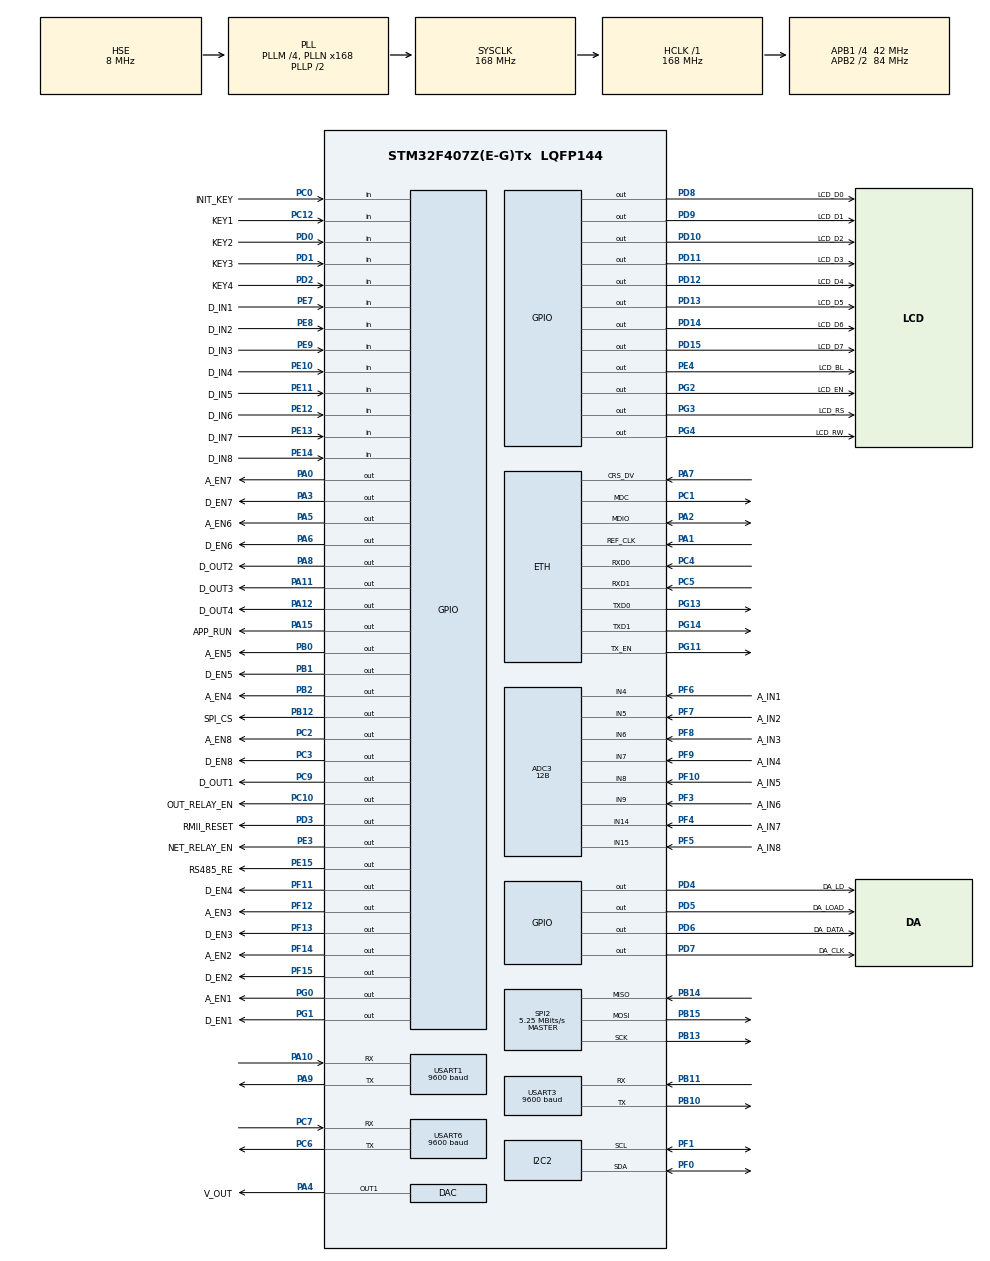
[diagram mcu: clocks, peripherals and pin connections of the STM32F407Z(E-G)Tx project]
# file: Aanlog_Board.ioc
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ADC3.Channel-0\#ChannelRegularConversion=ADC_CHANNEL_4
ADC3.Channel-1\#ChannelRegularConversion=ADC_CHANNEL_5
ADC3.Channel-2\#ChannelRegularConversion=ADC_CHANNEL_6
ADC3.Channel-3\#ChannelRegularConversion=ADC_CHANNEL_7
ADC3.Channel-4\#ChannelRegularConversion=ADC_CHANNEL_8
ADC3.Channel-5\#ChannelRegularConversion=ADC_CHANNEL_9
ADC3.Channel-6\#ChannelRegularConversion=ADC_CHANNEL_14
ADC3.Channel-7\#ChannelRegularConversion=ADC_CHANNEL_15
ADC3.ClockPrescaler=ADC_CLOCK_SYNC_PCLK_DIV4
ADC3.ContinuousConvMode=ENABLE
ADC3.DMAContinuousRequests=ENABLE
ADC3.DataAlign=ADC_DATAALIGN_RIGHT
ADC3.DiscontinuousConvMode=DISABLE
ADC3.EOCSelection=ADC_EOC_SINGLE_CONV
ADC3.EnableAnalogWatchDog=false
ADC3.ExternalTrigConv=ADC_SOFTWARE_START
ADC3.ExternalTrigConvEdge=ADC_EXTERNALTRIGCONVEDGE_NONE
ADC3.InjNumberOfConversion=0
ADC3.NbrOfConversion=8
ADC3.NbrOfConversionFlag=1
ADC3.Rank-0\#ChannelRegularConversion=1
ADC3.Rank-1\#ChannelRegularConversion=2
ADC3.Rank-2\#ChannelRegularConversion=3
ADC3.Rank-3\#ChannelRegularConversion=4
ADC3.Rank-4\#ChannelRegularConversion=5
ADC3.Rank-5\#ChannelRegularConversion=6
ADC3.Rank-6\#ChannelRegularConversion=7
ADC3.Rank-7\#ChannelRegularConversion=8
ADC3.Resolution=ADC_RESOLUTION_12B
ADC3.SamplingTime-0\#ChannelRegularConversion=ADC_SAMPLETIME_3CYCLES
ADC3.SamplingTime-1\#ChannelRegularConversion=ADC_SAMPLETIME_3CYCLES
ADC3.SamplingTime-2\#ChannelRegularConversion=ADC_SAMPLETIME_3CYCLES
ADC3.SamplingTime-3\#ChannelRegularConversion=ADC_SAMPLETIME_3CYCLES
ADC3.SamplingTime-4\#ChannelRegularConversion=ADC_SAMPLETIME_3CYCLES
ADC3.SamplingTime-5\#ChannelRegularConversion=ADC_SAMPLETIME_3CYCLES
ADC3.SamplingTime-6\#ChannelRegularConversion=ADC_SAMPLETIME_3CYCLES
ADC3.SamplingTime-7\#ChannelRegularConversion=ADC_SAMPLETIME_3CYCLES
ADC3.ScanConvMode=ENABLE
DAC.DAC_OutputBuffer=DAC_OUTPUTBUFFER_DISABLE
Dma.ADC3.0.Direction=DMA_PERIPH_TO_MEMORY
Dma.ADC3.0.FIFOMode=DMA_FIFOMODE_DISABLE
Dma.ADC3.0.Instance=DMA2_Stream1
Dma.ADC3.0.MemDataAlignment=DMA_MDATAALIGN_HALFWORD
Dma.ADC3.0.MemInc=DMA_MINC_ENABLE
Dma.ADC3.0.Mode=DMA_CIRCULAR
Dma.ADC3.0.PeriphDataAlignment=DMA_PDATAALIGN_HALFWORD
Dma.ADC3.0.PeriphInc=DMA_PINC_DISABLE
Dma.ADC3.0.Priority=DMA_PRIORITY_LOW
Dma.Request0=ADC3
ETH.AutoNegotiation=ETH_AUTONEGOTIATION_ENABLE
ETH.MediaInterface=ETH_MEDIA_INTERFACE_RMII
ETH.PHY_DUPLEX_STATUS=0x0010
ETH.PHY_Name_RMII=userPHY
ETH.PHY_SPEED_STATUS=0x0004
ETH.PHY_SR=0x1F
ETH.PHY_User_Name=LAN8720A
ETH.PhyAddress=0
LWIP.LWIP_DHCP=0
LWIP.LWIP_HTTPD=1
LWIP.MEMP_NUM_NETCONN=10
LWIP.MEM_SIZE=32000
LWIP.Version=v2.0.3_Cube
Mcu.Family=STM32F4
Mcu.Name=STM32F407Z(E-G)Tx
Mcu.Package=LQFP144
NVIC.ADC_IRQn=true\:0\:0\:false\:false\:true\:true
NVIC.DMA2_Stream1_IRQn=true\:0\:0\:true\:false\:true\:false
NVIC.ETH_IRQn=true\:0\:0\:true\:false\:true\:true
NVIC.PriorityGroup=NVIC_PRIORITYGROUP_4
NVIC.SPI2_IRQn=true\:0\:0\:false\:false\:true\:true
NVIC.TIM6_DAC_IRQn=true\:0\:0\:true\:false\:true\:false
NVIC.USART1_IRQn=true\:0\:0\:false\:false\:true\:true
NVIC.USART3_IRQn=true\:0\:0\:false\:false\:true\:true
NVIC.USART6_IRQn=true\:0\:0\:false\:false\:true\:true
NVIC.WWDG_IRQn=true\:0\:0\:false\:false\:true\:true
PA0-WKUP.GPIO_Label=A_EN7
PA0-WKUP.GPIO_PuPd=GPIO_NOPULL
PA0-WKUP.GPIO_Speed=GPIO_SPEED_FREQ_HIGH
PA0-WKUP.Signal=GPIO_Output
PA1.Mode=RMII
PA1.Signal=ETH_REF_CLK
PA10.Mode=Asynchronous
PA10.Signal=USART1_RX
PA11.GPIO_Label=D_OUT3
PA11.GPIO_PuPd=GPIO_PULLUP
PA11.GPIO_Speed=GPIO_SPEED_FREQ_HIGH
PA11.Signal=GPIO_Output
PA12.GPIO_Label=D_OUT4
PA12.GPIO_PuPd=GPIO_PULLUP
PA12.GPIO_Speed=GPIO_SPEED_FREQ_HIGH
PA12.Signal=GPIO_Output
PA15.GPIO_Label=APP_RUN
PA15.GPIO_Speed=GPIO_SPEED_FREQ_HIGH
PA15.Signal=GPIO_Output
PA2.Mode=RMII
PA2.Signal=ETH_MDIO
PA3.GPIO_Label=D_EN7
PA3.GPIO_PuPd=GPIO_NOPULL
PA3.GPIO_Speed=GPIO_SPEED_FREQ_HIGH
PA3.Signal=GPIO_Output
PA4.GPIO_Label=V_OUT
PA4.Signal=COMP_DAC1_group
PA5.GPIO_Label=A_EN6
PA5.GPIO_PuPd=GPIO_NOPULL
PA5.GPIO_Speed=GPIO_SPEED_FREQ_HIGH
PA5.Signal=GPIO_Output
PA6.GPIO_Label=D_EN6
PA6.GPIO_PuPd=GPIO_NOPULL
PA6.GPIO_Speed=GPIO_SPEED_FREQ_HIGH
PA6.Signal=GPIO_Output
PA7.Mode=RMII
PA7.Signal=ETH_CRS_DV
PA8.GPIO_Label=D_OUT2
PA8.GPIO_PuPd=GPIO_PULLUP
PA8.GPIO_Speed=GPIO_SPEED_FREQ_HIGH
PA8.Signal=GPIO_Output
PA9.Mode=Asynchronous
PA9.Signal=USART1_TX
PB0.GPIO_Label=A_EN5
PB0.GPIO_Speed=GPIO_SPEED_FREQ_HIGH
PB0.Signal=GPIO_Output
PB1.GPIO_Label=D_EN5
PB1.GPIO_PuPd=GPIO_NOPULL
PB1.GPIO_Speed=GPIO_SPEED_FREQ_HIGH
PB1.Signal=GPIO_Output
PB10.Mode=Asynchronous
PB10.Signal=USART3_TX
PB11.Mode=Asynchronous
PB11.Signal=USART3_RX
PB12.GPIO_Label=SPI_CS
PB12.GPIO_Speed=GPIO_SPEED_FREQ_HIGH
PB12.Signal=GPIO_Output
PB13.Mode=Full_Duplex_Master
PB13.Signal=SPI2_SCK
PB14.Mode=Full_Duplex_Master
PB14.Signal=SPI2_MISO
PB15.Mode=Full_Duplex_Master
PB15.Signal=SPI2_MOSI
PB2.GPIO_Label=A_EN4
PB2.GPIO_PuPd=GPIO_NOPULL
PB2.GPIO_Speed=GPIO_SPEED_FREQ_HIGH
PB2.Signal=GPIO_Output
PC0.GPIO_Label=INIT_KEY
PC0.GPIO_PuPd=GPIO_PULLDOWN
PC0.Signal=GPIO_Input
PC1.Mode=RMII
PC1.Signal=ETH_MDC
PC10.GPIO_Label=OUT_RELAY_EN
PC10.GPIO_Speed=GPIO_SPEED_FREQ_HIGH
PC10.Signal=GPIO_Output
PC12.GPIO_Label=KEY1
PC12.GPIO_PuPd=GPIO_PULLDOWN
PC12.Signal=GPIO_Input
PC2.GPIO_Label=A_EN8
PC2.GPIO_PuPd=GPIO_NOPULL
PC2.GPIO_Speed=GPIO_SPEED_FREQ_HIGH
PC2.Signal=GPIO_Output
PC3.GPIO_Label=D_EN8
PC3.GPIO_PuPd=GPIO_NOPULL
PC3.GPIO_Speed=GPIO_SPEED_FREQ_HIGH
PC3.Signal=GPIO_Output
PC4.Mode=RMII
PC4.Signal=ETH_RXD0
PC5.Mode=RMII
PC5.Signal=ETH_RXD1
PC6.Mode=Asynchronous
PC6.Signal=USART6_TX
PC7.Mode=Asynchronous
PC7.Signal=USART6_RX
PC9.GPIO_Label=D_OUT1
PC9.GPIO_PuPd=GPIO_PULLUP
PC9.GPIO_Speed=GPIO_SPEED_FREQ_HIGH
PC9.Signal=GPIO_Output
PD0.GPIO_Label=KEY2
PD0.GPIO_PuPd=GPIO_PULLDOWN
PD0.Signal=GPIO_Input
PD1.GPIO_Label=KEY3
PD1.GPIO_PuPd=GPIO_PULLDOWN
PD1.Signal=GPIO_Input
PD10.GPIO_Label=LCD_D2
PD10.GPIO_Speed=GPIO_SPEED_FREQ_HIGH
PD10.Signal=GPIO_Output
PD11.GPIO_Label=LCD_D3
PD11.GPIO_Speed=GPIO_SPEED_FREQ_HIGH
PD11.Signal=GPIO_Output
PD12.GPIO_Label=LCD_D4
PD12.GPIO_Speed=GPIO_SPEED_FREQ_HIGH
PD12.Signal=GPIO_Output
PD13.GPIO_Label=LCD_D5
PD13.GPIO_Speed=GPIO_SPEED_FREQ_HIGH
PD13.Signal=GPIO_Output
PD14.GPIO_Label=LCD_D6
PD14.GPIO_Speed=GPIO_SPEED_FREQ_HIGH
PD14.Signal=GPIO_Output
PD15.GPIO_Label=LCD_D7
PD15.GPIO_Speed=GPIO_SPEED_FREQ_HIGH
PD15.Signal=GPIO_Output
PD2.GPIO_Label=KEY4
PD2.GPIO_PuPd=GPIO_PULLDOWN
PD2.Signal=GPIO_Input
PD3.GPIO_Label=RMII_RESET
PD3.GPIO_PuPd=GPIO_PULLDOWN
PD3.GPIO_Speed=GPIO_SPEED_FREQ_HIGH
PD3.Signal=GPIO_Output
PD4.GPIO_Label=DA_LD
PD4.GPIO_PuPd=GPIO_NOPULL
PD4.GPIO_Speed=GPIO_SPEED_FREQ_HIGH
PD4.Signal=GPIO_Output
PD5.GPIO_Label=DA_LOAD
PD5.GPIO_PuPd=GPIO_NOPULL
PD5.GPIO_Speed=GPIO_SPEED_FREQ_HIGH
PD5.Signal=GPIO_Output
PD6.GPIO_Label=DA_DATA
PD6.GPIO_Speed=GPIO_SPEED_FREQ_HIGH
PD6.Signal=GPIO_Output
PD7.GPIO_Label=DA_CLK
PD7.GPIO_Speed=GPIO_SPEED_FREQ_HIGH
PD7.Signal=GPIO_Output
PD8.GPIO_Label=LCD_D0
PD8.GPIO_Speed=GPIO_SPEED_FREQ_HIGH
PD8.Signal=GPIO_Output
PD9.GPIO_Label=LCD_D1
PD9.GPIO_Speed=GPIO_SPEED_FREQ_HIGH
PD9.Signal=GPIO_Output
PE10.GPIO_Label=D_IN4
PE10.GPIO_PuPd=GPIO_PULLDOWN
PE10.Signal=GPIO_Input
PE11.GPIO_Label=D_IN5
PE11.GPIO_PuPd=GPIO_PULLDOWN
PE11.Signal=GPIO_Input
PE12.GPIO_Label=D_IN6
PE12.GPIO_PuPd=GPIO_PULLDOWN
PE12.Signal=GPIO_Input
PE13.GPIO_Label=D_IN7
PE13.GPIO_PuPd=GPIO_PULLDOWN
PE13.Signal=GPIO_Input
PE14.GPIO_Label=D_IN8
PE14.GPIO_PuPd=GPIO_PULLDOWN
PE14.Signal=GPIO_Input
PE15.GPIO_Label=RS485_RE
PE15.GPIO_PuPd=GPIO_NOPULL
PE15.GPIO_Speed=GPIO_SPEED_FREQ_HIGH
PE15.Signal=GPIO_Output
PE3.GPIO_Label=NET_RELAY_EN
PE3.GPIO_PuPd=GPIO_NOPULL
PE3.GPIO_Speed=GPIO_SPEED_FREQ_HIGH
PE3.Signal=GPIO_Output
PE4.GPIO_Label=LCD_BL
PE4.GPIO_Speed=GPIO_SPEED_FREQ_HIGH
PE4.Signal=GPIO_Output
PE7.GPIO_Label=D_IN1
PE7.GPIO_PuPd=GPIO_PULLDOWN
PE7.Signal=GPIO_Input
PE8.GPIO_Label=D_IN2
PE8.GPIO_PuPd=GPIO_PULLDOWN
PE8.Signal=GPIO_Input
PE9.GPIO_Label=D_IN3
PE9.GPIO_PuPd=GPIO_PULLDOWN
PE9.Signal=GPIO_Input
PF0.Mode=I2C
PF0.Signal=I2C2_SDA
PF1.Mode=I2C
PF1.Signal=I2C2_SCL
PF10.GPIO_Label=A_IN5
PF10.Mode=IN8
PF10.Signal=ADC3_IN8
PF11.GPIO_Label=D_EN4
PF11.GPIO_PuPd=GPIO_NOPULL
PF11.GPIO_Speed=GPIO_SPEED_FREQ_HIGH
PF11.Signal=GPIO_Output
PF12.GPIO_Label=A_EN3
PF12.GPIO_PuPd=GPIO_NOPULL
PF12.GPIO_Speed=GPIO_SPEED_FREQ_HIGH
PF12.Signal=GPIO_Output
PF13.GPIO_Label=D_EN3
PF13.GPIO_PuPd=GPIO_NOPULL
PF13.GPIO_Speed=GPIO_SPEED_FREQ_HIGH
PF13.Signal=GPIO_Output
PF14.GPIO_Label=A_EN2
PF14.GPIO_PuPd=GPIO_NOPULL
PF14.GPIO_Speed=GPIO_SPEED_FREQ_HIGH
PF14.Signal=GPIO_Output
PF15.GPIO_Label=D_EN2
PF15.GPIO_PuPd=GPIO_NOPULL
PF15.GPIO_Speed=GPIO_SPEED_FREQ_HIGH
PF15.Signal=GPIO_Output
PF3.GPIO_Label=A_IN6
PF3.Mode=IN9
PF3.Signal=ADC3_IN9
PF4.GPIO_Label=A_IN7
PF4.Mode=IN14
PF4.Signal=ADC3_IN14
PF5.GPIO_Label=A_IN8
PF5.Mode=IN15
PF5.Signal=ADC3_IN15
PF6.GPIO_Label=A_IN1
PF6.Mode=IN4
PF6.Signal=ADC3_IN4
PF7.GPIO_Label=A_IN2
PF7.Mode=IN5
PF7.Signal=ADC3_IN5
PF8.GPIO_Label=A_IN3
PF8.Mode=IN6
PF8.Signal=ADC3_IN6
PF9.GPIO_Label=A_IN4
PF9.Mode=IN7
PF9.Signal=ADC3_IN7
PG0.GPIO_Label=A_EN1
PG0.GPIO_PuPd=GPIO_NOPULL
PG0.GPIO_Speed=GPIO_SPEED_FREQ_HIGH
PG0.Signal=GPIO_Output
PG1.GPIO_Label=D_EN1
PG1.GPIO_PuPd=GPIO_NOPULL
PG1.GPIO_Speed=GPIO_SPEED_FREQ_HIGH
PG1.Signal=GPIO_Output
PG11.Mode=RMII
PG11.Signal=ETH_TX_EN
PG13.Mode=RMII
PG13.Signal=ETH_TXD0
PG14.Mode=RMII
PG14.Signal=ETH_TXD1
PG2.GPIO_Label=LCD_EN
PG2.GPIO_PuPd=GPIO_NOPULL
PG2.GPIO_Speed=GPIO_SPEED_FREQ_HIGH
PG2.Signal=GPIO_Output
PG3.GPIO_Label=LCD_RS
PG3.GPIO_Speed=GPIO_SPEED_FREQ_HIGH
PG3.Signal=GPIO_Output
PG4.GPIO_Label=LCD_RW
PG4.GPIO_Speed=GPIO_SPEED_FREQ_HIGH
PG4.Signal=GPIO_Output
PH0-OSC_IN.Mode=HSE-External-Oscillator
PH0-OSC_IN.Signal=RCC_OSC_IN
PH1-OSC_OUT.Mode=HSE-External-Oscillator
PH1-OSC_OUT.Signal=RCC_OSC_OUT
ProjectManager.HeapSize=0x200
ProjectManager.StackSize=0x400
ProjectManager.TargetToolchain=MDK-ARM V5
RCC.48MHZClocksFreq_Value=84000000
RCC.AHBFreq_Value=168000000
RCC.APB1CLKDivider=RCC_HCLK_DIV4
RCC.APB1Freq_Value=42000000
RCC.APB1TimFreq_Value=84000000
RCC.APB2CLKDivider=RCC_HCLK_DIV2
RCC.APB2Freq_Value=84000000
RCC.APB2TimFreq_Value=168000000
RCC.CortexFreq_Value=168000000
RCC.HCLKFreq_Value=168000000
RCC.HSE_VALUE=8000000
RCC.HSI_VALUE=16000000
RCC.LSE_VALUE=32768
RCC.PLLM=4
RCC.PLLN=168
RCC.PLLSourceVirtual=RCC_PLLSOURCE_HSE
RCC.RCC_RTC_Clock_SourceVirtual=RCC_RTCCLKSOURCE_HSE_DIV8
RCC.RCC_RTC_Clock_Source_FROM_HSE=RCC_RTCCLKSOURCE_HSE_DIV8
RCC.SYSCLKFreq_VALUE=168000000
RCC.SYSCLKSource=RCC_SYSCLKSOURCE_PLLCLK
RCC.VCOOutputFreq_Value=336000000
RTC.Format=RTC_FORMAT_BIN
RTC.SynchPrediv=7812
SH.COMP_DAC1_group.0=DAC_OUT1,DAC_OUT1
SPI2.BaudRatePrescaler=SPI_BAUDRATEPRESCALER_8
SPI2.CLKPhase=SPI_PHASE_2EDGE
SPI2.CLKPolarity=SPI_POLARITY_HIGH
SPI2.CalculateBaudRate=5.25 MBits/s
SPI2.Direction=SPI_DIRECTION_2LINES
SPI2.Mode=SPI_MODE_MASTER
SPI2.TIMode=SPI_TIMODE_DISABLE
SPI2.VirtualType=VM_MASTER
USART1.BaudRate=9600
USART1.VirtualMode=VM_ASYNC
USART3.BaudRate=9600
USART3.VirtualMode=VM_ASYNC
USART6.BaudRate=9600
USART6.VirtualMode=VM_ASYNC
VP_LWIP_VS_Enabled.Mode=Enabled
VP_RTC_VS_RTC_Activate.Mode=RTC_Enabled
VP_RTC_VS_RTC_Calendar.Mode=RTC_Calendar
VP_WWDG_VS_WWDG.Mode=WWDG_Activate
WWDG.Counter=0x7F
WWDG.EWIMode=WWDG_EWI_ENABLE
WWDG.Prescaler=WWDG_PRESCALER_8
WWDG.Window=0x5A
board=Aanlog_Board

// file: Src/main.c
/**
  ******************************************************************************
  * @file           : main.c
  * @brief          : Main program body
  ******************************************************************************
  * This notice applies to any and all portions of this file
  * that are not between comment pairs USER CODE BEGIN and
  * USER CODE END. Other portions of this file, whether
  * inserted by the user or by software development tools
  * are owned by their respective copyright owners.
  *
  * Copyright (c) 2018 STMicroelectronics International N.V.
  * All rights reserved.
  *
  * Redistribution and use in source and binary forms, with or without
  * modification, are permitted, provided that the following conditions are met:
  *
  * 1. Redistribution of source code must retain the above copyright notice,
  *    this list of conditions and the following disclaimer.
  * 2. Redistributions in binary form must reproduce the above copyright notice,
  *    this list of conditions and the following disclaimer in the documentation
  *    and/or other materials provided with the distribution.
  * 3. Neither the name of STMicroelectronics nor the names of other
  *    contributors to this software may be used to endorse or promote products
  *    derived from this software without specific written permission.
  * 4. This software, including modifications and/or derivative works of this
  *    software, must execute solely and exclusively on microcontroller or
  *    microprocessor devices manufactured by or for STMicroelectronics.
  * 5. Redistribution and use of this software other than as permitted under
  *    this license is void and will automatically terminate your rights under
  *    this license.
  *
  * THIS SOFTWARE IS PROVIDED BY STMICROELECTRONICS AND CONTRIBUTORS "AS IS"
  * AND ANY EXPRESS, IMPLIED OR STATUTORY WARRANTIES, INCLUDING, BUT NOT
  * LIMITED TO, THE IMPLIED WARRANTIES OF MERCHANTABILITY, FITNESS FOR A
  * PARTICULAR PURPOSE AND NON-INFRINGEMENT OF THIRD PARTY INTELLECTUAL PROPERTY
  * RIGHTS ARE DISCLAIMED TO THE FULLEST EXTENT PERMITTED BY LAW. IN NO EVENT
  * SHALL STMICROELECTRONICS OR CONTRIBUTORS BE LIABLE FOR ANY DIRECT, INDIRECT,
  * INCIDENTAL, SPECIAL, EXEMPLARY, OR CONSEQUENTIAL DAMAGES (INCLUDING, BUT NOT
  * LIMITED TO, PROCUREMENT OF SUBSTITUTE GOODS OR SERVICES; LOSS OF USE, DATA,
  * OR PROFITS; OR BUSINESS INTERRUPTION) HOWEVER CAUSED AND ON ANY THEORY OF
  * LIABILITY, WHETHER IN CONTRACT, STRICT LIABILITY, OR TORT (INCLUDING
  * NEGLIGENCE OR OTHERWISE) ARISING IN ANY WAY OUT OF THE USE OF THIS SOFTWARE,
  * EVEN IF ADVISED OF THE POSSIBILITY OF SUCH DAMAGE.
  *
  ******************************************************************************
  */
#include "main.h"
#include "stm32f4xx_hal.h"
#include "lwip.h"

/* USER CODE BEGIN Includes */
#include <platform.h>
extern struct netif gnetif;
/* USER CODE END Includes */

ADC_HandleTypeDef hadc3;
DMA_HandleTypeDef hdma_adc3;

DAC_HandleTypeDef hdac;

I2C_HandleTypeDef hi2c2;

RTC_HandleTypeDef hrtc;

SPI_HandleTypeDef hspi2;

UART_HandleTypeDef huart1;
UART_HandleTypeDef huart3;
UART_HandleTypeDef huart6;

WWDG_HandleTypeDef hwwdg;

/* USER CODE BEGIN PV */
/* Private variables ---------------------------------------------------------*/

/* USER CODE END PV */

void SystemClock_Config(void);
static void MX_GPIO_Init(void);
static void MX_DMA_Init(void);
static void MX_ADC3_Init(void);
static void MX_I2C2_Init(void);
static void MX_SPI2_Init(void);
static void MX_USART1_UART_Init(void);
static void MX_USART6_UART_Init(void);
static void MX_USART3_UART_Init(void);
static void MX_DAC_Init(void);
static void MX_WWDG_Init(void);
static void MX_RTC_Init(void);

/* USER CODE BEGIN PFP */
/* Private function prototypes -----------------------------------------------*/

/* USER CODE END PFP */

int main(void)
{
  /* USER CODE BEGIN 1 */
	SCB->VTOR = FLASH_BASE | 0x10000;
	__set_FAULTMASK(0);
  /* USER CODE END 1 */

  /* MCU Configuration----------------------------------------------------------*/

  /* Reset of all peripherals, Initializes the Flash interface and the Systick. */
  HAL_Init();

  /* Configure the system clock */
  SystemClock_Config();

  /* Initialize all configured peripherals */
  MX_GPIO_Init();
  MX_DMA_Init();
  MX_ADC3_Init();
  MX_I2C2_Init();
  MX_SPI2_Init();
  MX_USART1_UART_Init();
  MX_USART6_UART_Init();
  MX_USART3_UART_Init();
  MX_DAC_Init();
  //MX_LWIP_Init();

  MX_RTC_Init();
  /* USER CODE BEGIN 2 */
	PLATFORM_Init();
	MX_LWIP_Init();
  my_http_init();

	HAL_GPIO_WritePin(NET_RELAY_EN_GPIO_Port, NET_RELAY_EN_Pin, GPIO_PIN_SET);   //使能网络
	HAL_GPIO_WritePin(OUT_RELAY_EN_GPIO_Port, OUT_RELAY_EN_Pin, GPIO_PIN_SET);   //使能继电器输出

	//static RTC_TimeTypeDef stimestructureget;
	//static RTC_DateTypeDef sdatestructureget;

	static uint32_t Tick = 0;
	Tick = HAL_GetTick();
	static uint32_t Init_tick = 0;
	if(eMBTCPInit(502) != MB_ENOERR)
		Soft_Reset();
	eMBEnable();

	MX_WWDG_Init();
  /* USER CODE END 2 */

  /* Infinite loop */
  while (1)
  {

  /* USER CODE BEGIN 3 */
		eMBPoll();
		if(HAL_GetTick() - Tick >= 1000) {

			HAL_GPIO_TogglePin(APP_RUN_GPIO_Port, APP_RUN_Pin);
			Tick = HAL_GetTick();
			//检测内存
			struct tcp_seg *seg = (struct tcp_seg *)memp_malloc(MEMP_TCP_SEG);
			if(seg == NULL)
				Soft_Reset();
			memp_free(MEMP_TCP_SEG, seg);

		}
		if(HAL_GPIO_ReadPin(INIT_KEY_GPIO_Port, INIT_KEY_Pin) == GPIO_PIN_SET)
			Init_tick = 0;
		if(HAL_GPIO_ReadPin(INIT_KEY_GPIO_Port, INIT_KEY_Pin) == GPIO_PIN_RESET && !Init_tick) {
			Init_tick = HAL_GetTick();
		}
		if(Init_tick && HAL_GetTick() - Init_tick >= 3000) {
			Init_tick = HAL_GetTick();
			ClearSysInfo();
			Soft_Reset();
		}
		WWDG_Refresh();
		MX_LWIP_Process();
  }
  /* USER CODE END 3 */

}

void SystemClock_Config(void)
{

  RCC_OscInitTypeDef RCC_OscInitStruct;
  RCC_ClkInitTypeDef RCC_ClkInitStruct;
  RCC_PeriphCLKInitTypeDef PeriphClkInitStruct;

    /**Configure the main internal regulator output voltage
    */
  __HAL_RCC_PWR_CLK_ENABLE();

  __HAL_PWR_VOLTAGESCALING_CONFIG(PWR_REGULATOR_VOLTAGE_SCALE1);

    /**Initializes the CPU, AHB and APB busses clocks
    */
  RCC_OscInitStruct.OscillatorType = RCC_OSCILLATORTYPE_HSE;
  RCC_OscInitStruct.HSEState = RCC_HSE_ON;
  RCC_OscInitStruct.PLL.PLLState = RCC_PLL_ON;
  RCC_OscInitStruct.PLL.PLLSource = RCC_PLLSOURCE_HSE;
  RCC_OscInitStruct.PLL.PLLM = 4;
  RCC_OscInitStruct.PLL.PLLN = 168;
  RCC_OscInitStruct.PLL.PLLP = RCC_PLLP_DIV2;
  RCC_OscInitStruct.PLL.PLLQ = 4;
  if (HAL_RCC_OscConfig(&RCC_OscInitStruct) != HAL_OK)
  {
    _Error_Handler(__FILE__, __LINE__);
  }

    /**Initializes the CPU, AHB and APB busses clocks
    */
  RCC_ClkInitStruct.ClockType = RCC_CLOCKTYPE_HCLK|RCC_CLOCKTYPE_SYSCLK
                              |RCC_CLOCKTYPE_PCLK1|RCC_CLOCKTYPE_PCLK2;
  RCC_ClkInitStruct.SYSCLKSource = RCC_SYSCLKSOURCE_PLLCLK;
  RCC_ClkInitStruct.AHBCLKDivider = RCC_SYSCLK_DIV1;
  RCC_ClkInitStruct.APB1CLKDivider = RCC_HCLK_DIV4;
  RCC_ClkInitStruct.APB2CLKDivider = RCC_HCLK_DIV2;

  if (HAL_RCC_ClockConfig(&RCC_ClkInitStruct, FLASH_LATENCY_5) != HAL_OK)
  {
    _Error_Handler(__FILE__, __LINE__);
  }

  PeriphClkInitStruct.PeriphClockSelection = RCC_PERIPHCLK_RTC;
  PeriphClkInitStruct.RTCClockSelection = RCC_RTCCLKSOURCE_HSE_DIV8;
  if (HAL_RCCEx_PeriphCLKConfig(&PeriphClkInitStruct) != HAL_OK)
  {
    _Error_Handler(__FILE__, __LINE__);
  }

    /**Configure the Systick interrupt time
    */
  HAL_SYSTICK_Config(HAL_RCC_GetHCLKFreq()/1000);

    /**Configure the Systick
    */
  HAL_SYSTICK_CLKSourceConfig(SYSTICK_CLKSOURCE_HCLK);

  /* SysTick_IRQn interrupt configuration */
  HAL_NVIC_SetPriority(SysTick_IRQn, 0, 0);
}

/* ADC3 init function */
static void MX_ADC3_Init(void)
{

  ADC_ChannelConfTypeDef sConfig;

    /**Configure the global features of the ADC (Clock, Resolution, Data Alignment and number of conversion)
    */
  hadc3.Instance = ADC3;
  hadc3.Init.ClockPrescaler = ADC_CLOCK_SYNC_PCLK_DIV4;
  hadc3.Init.Resolution = ADC_RESOLUTION_12B;
  hadc3.Init.ScanConvMode = ENABLE;
  hadc3.Init.ContinuousConvMode = ENABLE;
  hadc3.Init.DiscontinuousConvMode = DISABLE;
  hadc3.Init.ExternalTrigConvEdge = ADC_EXTERNALTRIGCONVEDGE_NONE;
  hadc3.Init.ExternalTrigConv = ADC_SOFTWARE_START;
  hadc3.Init.DataAlign = ADC_DATAALIGN_RIGHT;
  hadc3.Init.NbrOfConversion = 8;
  hadc3.Init.DMAContinuousRequests = ENABLE;
  hadc3.Init.EOCSelection = ADC_EOC_SINGLE_CONV;
  if (HAL_ADC_Init(&hadc3) != HAL_OK)
  {
    _Error_Handler(__FILE__, __LINE__);
  }

    /**Configure for the selected ADC regular channel its corresponding rank in the sequencer and its sample time.
    */
  sConfig.Channel = ADC_CHANNEL_4;
  sConfig.Rank = 1;
  sConfig.SamplingTime = ADC_SAMPLETIME_3CYCLES;
  if (HAL_ADC_ConfigChannel(&hadc3, &sConfig) != HAL_OK)
  {
    _Error_Handler(__FILE__, __LINE__);
  }

    /**Configure for the selected ADC regular channel its corresponding rank in the sequencer and its sample time.
    */
  sConfig.Channel = ADC_CHANNEL_5;
  sConfig.Rank = 2;
  if (HAL_ADC_ConfigChannel(&hadc3, &sConfig) != HAL_OK)
  {
    _Error_Handler(__FILE__, __LINE__);
  }

    /**Configure for the selected ADC regular channel its corresponding rank in the sequencer and its sample time.
    */
  sConfig.Channel = ADC_CHANNEL_6;
  sConfig.Rank = 3;
  if (HAL_ADC_ConfigChannel(&hadc3, &sConfig) != HAL_OK)
  {
    _Error_Handler(__FILE__, __LINE__);
  }

    /**Configure for the selected ADC regular channel its corresponding rank in the sequencer and its sample time.
    */
  sConfig.Channel = ADC_CHANNEL_7;
  sConfig.Rank = 4;
  if (HAL_ADC_ConfigChannel(&hadc3, &sConfig) != HAL_OK)
  {
    _Error_Handler(__FILE__, __LINE__);
  }

    /**Configure for the selected ADC regular channel its corresponding rank in the sequencer and its sample time.
    */
  sConfig.Channel = ADC_CHANNEL_8;
  sConfig.Rank = 5;
  if (HAL_ADC_ConfigChannel(&hadc3, &sConfig) != HAL_OK)
  {
    _Error_Handler(__FILE__, __LINE__);
  }

    /**Configure for the selected ADC regular channel its corresponding rank in the sequencer and its sample time.
    */
  sConfig.Channel = ADC_CHANNEL_9;
  sConfig.Rank = 6;
  if (HAL_ADC_ConfigChannel(&hadc3, &sConfig) != HAL_OK)
  {
    _Error_Handler(__FILE__, __LINE__);
  }

    /**Configure for the selected ADC regular channel its corresponding rank in the sequencer and its sample time.
    */
  sConfig.Channel = ADC_CHANNEL_14;
  sConfig.Rank = 7;
  if (HAL_ADC_ConfigChannel(&hadc3, &sConfig) != HAL_OK)
  {
    _Error_Handler(__FILE__, __LINE__);
  }

    /**Configure for the selected ADC regular channel its corresponding rank in the sequencer and its sample time.
    */
  sConfig.Channel = ADC_CHANNEL_15;
  sConfig.Rank = 8;
  if (HAL_ADC_ConfigChannel(&hadc3, &sConfig) != HAL_OK)
  {
    _Error_Handler(__FILE__, __LINE__);
  }

}

/* DAC init function */
static void MX_DAC_Init(void)
{

  DAC_ChannelConfTypeDef sConfig;

    /**DAC Initialization
    */
  hdac.Instance = DAC;
  if (HAL_DAC_Init(&hdac) != HAL_OK)
  {
    _Error_Handler(__FILE__, __LINE__);
  }

    /**DAC channel OUT1 config
    */
  sConfig.DAC_Trigger = DAC_TRIGGER_NONE;
  sConfig.DAC_OutputBuffer = DAC_OUTPUTBUFFER_DISABLE;
  if (HAL_DAC_ConfigChannel(&hdac, &sConfig, DAC_CHANNEL_1) != HAL_OK)
  {
    _Error_Handler(__FILE__, __LINE__);
  }

}

/* I2C2 init function */
static void MX_I2C2_Init(void)
{

  hi2c2.Instance = I2C2;
  hi2c2.Init.ClockSpeed = 100000;
  hi2c2.Init.DutyCycle = I2C_DUTYCYCLE_2;
  hi2c2.Init.OwnAddress1 = 0;
  hi2c2.Init.AddressingMode = I2C_ADDRESSINGMODE_7BIT;
  hi2c2.Init.DualAddressMode = I2C_DUALADDRESS_DISABLE;
  hi2c2.Init.OwnAddress2 = 0;
  hi2c2.Init.GeneralCallMode = I2C_GENERALCALL_DISABLE;
  hi2c2.Init.NoStretchMode = I2C_NOSTRETCH_DISABLE;
  if (HAL_I2C_Init(&hi2c2) != HAL_OK)
  {
    _Error_Handler(__FILE__, __LINE__);
  }

}

/* RTC init function */
static void MX_RTC_Init(void)
{

  RTC_TimeTypeDef sTime;
  RTC_DateTypeDef sDate;

    /**Initialize RTC Only
    */
  hrtc.Instance = RTC;
if(HAL_RTCEx_BKUPRead(&hrtc, RTC_BKP_DR0) != 0x32F2){
  hrtc.Init.HourFormat = RTC_HOURFORMAT_24;
  hrtc.Init.AsynchPrediv = 127;
  hrtc.Init.SynchPrediv = 7812;
  hrtc.Init.OutPut = RTC_OUTPUT_DISABLE;
  hrtc.Init.OutPutPolarity = RTC_OUTPUT_POLARITY_HIGH;
  hrtc.Init.OutPutType = RTC_OUTPUT_TYPE_OPENDRAIN;
  if (HAL_RTC_Init(&hrtc) != HAL_OK)
  {
    _Error_Handler(__FILE__, __LINE__);
  }

    /**Initialize RTC and set the Time and Date
    */
  sTime.Hours = 0;
  sTime.Minutes = 0;
  sTime.Seconds = 0;
  sTime.DayLightSaving = RTC_DAYLIGHTSAVING_NONE;
  sTime.StoreOperation = RTC_STOREOPERATION_RESET;
  if (HAL_RTC_SetTime(&hrtc, &sTime, RTC_FORMAT_BIN) != HAL_OK)
  {
    _Error_Handler(__FILE__, __LINE__);
  }

  sDate.WeekDay = RTC_WEEKDAY_MONDAY;
  sDate.Month = RTC_MONTH_JANUARY;
  sDate.Date = 1;
  sDate.Year = 0;

  if (HAL_RTC_SetDate(&hrtc, &sDate, RTC_FORMAT_BIN) != HAL_OK)
  {
    _Error_Handler(__FILE__, __LINE__);
  }

    HAL_RTCEx_BKUPWrite(&hrtc,RTC_BKP_DR0,0x32F2);
  }

}

/* SPI2 init function */
static void MX_SPI2_Init(void)
{

  /* SPI2 parameter configuration*/
  hspi2.Instance = SPI2;
  hspi2.Init.Mode = SPI_MODE_MASTER;
  hspi2.Init.Direction = SPI_DIRECTION_2LINES;
  hspi2.Init.DataSize = SPI_DATASIZE_8BIT;
  hspi2.Init.CLKPolarity = SPI_POLARITY_HIGH;
  hspi2.Init.CLKPhase = SPI_PHASE_2EDGE;
  hspi2.Init.NSS = SPI_NSS_SOFT;
  hspi2.Init.BaudRatePrescaler = SPI_BAUDRATEPRESCALER_8;
  hspi2.Init.FirstBit = SPI_FIRSTBIT_MSB;
  hspi2.Init.TIMode = SPI_TIMODE_DISABLE;
  hspi2.Init.CRCCalculation = SPI_CRCCALCULATION_DISABLE;
  hspi2.Init.CRCPolynomial = 10;
  if (HAL_SPI_Init(&hspi2) != HAL_OK)
  {
    _Error_Handler(__FILE__, __LINE__);
  }

}

/* USART1 init function */
static void MX_USART1_UART_Init(void)
{

  huart1.Instance = USART1;
  huart1.Init.BaudRate = 9600;
  huart1.Init.WordLength = UART_WORDLENGTH_8B;
  huart1.Init.StopBits = UART_STOPBITS_1;
  huart1.Init.Parity = UART_PARITY_NONE;
  huart1.Init.Mode = UART_MODE_TX_RX;
  huart1.Init.HwFlowCtl = UART_HWCONTROL_NONE;
  huart1.Init.OverSampling = UART_OVERSAMPLING_16;
  if (HAL_UART_Init(&huart1) != HAL_OK)
  {
    _Error_Handler(__FILE__, __LINE__);
  }

}

/* USART3 init function */
static void MX_USART3_UART_Init(void)
{

  huart3.Instance = USART3;
  huart3.Init.BaudRate = 9600;
  huart3.Init.WordLength = UART_WORDLENGTH_8B;
  huart3.Init.StopBits = UART_STOPBITS_1;
  huart3.Init.Parity = UART_PARITY_NONE;
  huart3.Init.Mode = UART_MODE_TX_RX;
  huart3.Init.HwFlowCtl = UART_HWCONTROL_NONE;
  huart3.Init.OverSampling = UART_OVERSAMPLING_16;
  if (HAL_UART_Init(&huart3) != HAL_OK)
  {
    _Error_Handler(__FILE__, __LINE__);
  }

}

/* USART6 init function */
static void MX_USART6_UART_Init(void)
{

  huart6.Instance = USART6;
  huart6.Init.BaudRate = 9600;
  huart6.Init.WordLength = UART_WORDLENGTH_8B;
  huart6.Init.StopBits = UART_STOPBITS_1;
  huart6.Init.Parity = UART_PARITY_NONE;
  huart6.Init.Mode = UART_MODE_TX_RX;
  huart6.Init.HwFlowCtl = UART_HWCONTROL_NONE;
  huart6.Init.OverSampling = UART_OVERSAMPLING_16;
  if (HAL_UART_Init(&huart6) != HAL_OK)
  {
    _Error_Handler(__FILE__, __LINE__);
  }

}

/* WWDG init function */
static void MX_WWDG_Init(void)
{

  hwwdg.Instance = WWDG;
  hwwdg.Init.Prescaler = WWDG_PRESCALER_8;
  hwwdg.Init.Window = 0x5A;
  hwwdg.Init.Counter = 0x7F;
  hwwdg.Init.EWIMode = WWDG_EWI_ENABLE;
  if (HAL_WWDG_Init(&hwwdg) != HAL_OK)
  {
    _Error_Handler(__FILE__, __LINE__);
  }

}

static void MX_DMA_Init(void)
{
  /* DMA controller clock enable */
  __HAL_RCC_DMA2_CLK_ENABLE();

  /* DMA interrupt init */
  /* DMA2_Stream1_IRQn interrupt configuration */
  HAL_NVIC_SetPriority(DMA2_Stream1_IRQn, 0, 0);
  HAL_NVIC_EnableIRQ(DMA2_Stream1_IRQn);

}

/** Configure pins as
        * Analog
        * Input
        * Output
        * EVENT_OUT
        * EXTI
*/
static void MX_GPIO_Init(void)
{

  GPIO_InitTypeDef GPIO_InitStruct;

  /* GPIO Ports Clock Enable */
  __HAL_RCC_GPIOE_CLK_ENABLE();
  __HAL_RCC_GPIOF_CLK_ENABLE();
  __HAL_RCC_GPIOH_CLK_ENABLE();
  __HAL_RCC_GPIOC_CLK_ENABLE();
  __HAL_RCC_GPIOA_CLK_ENABLE();
  __HAL_RCC_GPIOB_CLK_ENABLE();
  __HAL_RCC_GPIOG_CLK_ENABLE();
  __HAL_RCC_GPIOD_CLK_ENABLE();

  /*Configure GPIO pin Output Level */
  HAL_GPIO_WritePin(GPIOE, NET_RELAY_EN_Pin|LCD_BL_Pin|RS485_RE_Pin, GPIO_PIN_RESET);

  /*Configure GPIO pin Output Level */
  HAL_GPIO_WritePin(GPIOC, A_EN8_Pin|D_EN8_Pin|D_OUT1_Pin|OUT_RELAY_EN_Pin, GPIO_PIN_RESET);

  /*Configure GPIO pin Output Level */
  HAL_GPIO_WritePin(GPIOA, A_EN7_Pin|D_EN7_Pin|A_EN6_Pin|D_EN6_Pin
                          |D_OUT2_Pin|D_OUT3_Pin|D_OUT4_Pin|APP_RUN_Pin, GPIO_PIN_RESET);

  /*Configure GPIO pin Output Level */
  HAL_GPIO_WritePin(GPIOB, A_EN5_Pin|D_EN5_Pin|A_EN4_Pin|SPI_CS_Pin, GPIO_PIN_RESET);

  /*Configure GPIO pin Output Level */
  HAL_GPIO_WritePin(GPIOF, D_EN4_Pin|A_EN3_Pin|D_EN3_Pin|A_EN2_Pin
                          |D_EN2_Pin, GPIO_PIN_RESET);

  /*Configure GPIO pin Output Level */
  HAL_GPIO_WritePin(GPIOG, A_EN1_Pin|D_EN1_Pin|LCD_EN_Pin|LCD_RS_Pin
                          |LCD_RW_Pin, GPIO_PIN_RESET);

  /*Configure GPIO pin Output Level */
  HAL_GPIO_WritePin(GPIOD, LCD_D0_Pin|LCD_D1_Pin|LCD_D2_Pin|LCD_D3_Pin
                          |LCD_D4_Pin|LCD_D5_Pin|LCD_D6_Pin|LCD_D7_Pin
                          |RMII_RESET_Pin|DA_LD_Pin|DA_LOAD_Pin|DA_DATA_Pin
                          |DA_CLK_Pin, GPIO_PIN_RESET);

  /*Configure GPIO pins : NET_RELAY_EN_Pin LCD_BL_Pin RS485_RE_Pin */
  GPIO_InitStruct.Pin = NET_RELAY_EN_Pin|LCD_BL_Pin|RS485_RE_Pin;
  GPIO_InitStruct.Mode = GPIO_MODE_OUTPUT_PP;
  GPIO_InitStruct.Pull = GPIO_NOPULL;
  GPIO_InitStruct.Speed = GPIO_SPEED_FREQ_HIGH;
  HAL_GPIO_Init(GPIOE, &GPIO_InitStruct);

  /*Configure GPIO pins : INIT_KEY_Pin KEY1_Pin */
  GPIO_InitStruct.Pin = INIT_KEY_Pin|KEY1_Pin;
  GPIO_InitStruct.Mode = GPIO_MODE_INPUT;
  GPIO_InitStruct.Pull = GPIO_PULLDOWN;
  HAL_GPIO_Init(GPIOC, &GPIO_InitStruct);

  /*Configure GPIO pins : A_EN8_Pin D_EN8_Pin OUT_RELAY_EN_Pin */
  GPIO_InitStruct.Pin = A_EN8_Pin|D_EN8_Pin|OUT_RELAY_EN_Pin;
  GPIO_InitStruct.Mode = GPIO_MODE_OUTPUT_PP;
  GPIO_InitStruct.Pull = GPIO_NOPULL;
  GPIO_InitStruct.Speed = GPIO_SPEED_FREQ_HIGH;
  HAL_GPIO_Init(GPIOC, &GPIO_InitStruct);

  /*Configure GPIO pins : A_EN7_Pin D_EN7_Pin A_EN6_Pin D_EN6_Pin
                           APP_RUN_Pin */
  GPIO_InitStruct.Pin = A_EN7_Pin|D_EN7_Pin|A_EN6_Pin|D_EN6_Pin
                          |APP_RUN_Pin;
  GPIO_InitStruct.Mode = GPIO_MODE_OUTPUT_PP;
  GPIO_InitStruct.Pull = GPIO_NOPULL;
  GPIO_InitStruct.Speed = GPIO_SPEED_FREQ_HIGH;
  HAL_GPIO_Init(GPIOA, &GPIO_InitStruct);

  /*Configure GPIO pins : A_EN5_Pin D_EN5_Pin A_EN4_Pin SPI_CS_Pin */
  GPIO_InitStruct.Pin = A_EN5_Pin|D_EN5_Pin|A_EN4_Pin|SPI_CS_Pin;
  GPIO_InitStruct.Mode = GPIO_MODE_OUTPUT_PP;
  GPIO_InitStruct.Pull = GPIO_NOPULL;
  GPIO_InitStruct.Speed = GPIO_SPEED_FREQ_HIGH;
  HAL_GPIO_Init(GPIOB, &GPIO_InitStruct);

  /*Configure GPIO pins : D_EN4_Pin A_EN3_Pin D_EN3_Pin A_EN2_Pin
                           D_EN2_Pin */
  GPIO_InitStruct.Pin = D_EN4_Pin|A_EN3_Pin|D_EN3_Pin|A_EN2_Pin
                          |D_EN2_Pin;
  GPIO_InitStruct.Mode = GPIO_MODE_OUTPUT_PP;
  GPIO_InitStruct.Pull = GPIO_NOPULL;
  GPIO_InitStruct.Speed = GPIO_SPEED_FREQ_HIGH;
  HAL_GPIO_Init(GPIOF, &GPIO_InitStruct);

  /*Configure GPIO pins : A_EN1_Pin D_EN1_Pin LCD_EN_Pin LCD_RS_Pin
                           LCD_RW_Pin */
  GPIO_InitStruct.Pin = A_EN1_Pin|D_EN1_Pin|LCD_EN_Pin|LCD_RS_Pin
                          |LCD_RW_Pin;
  GPIO_InitStruct.Mode = GPIO_MODE_OUTPUT_PP;
  GPIO_InitStruct.Pull = GPIO_NOPULL;
  GPIO_InitStruct.Speed = GPIO_SPEED_FREQ_HIGH;
  HAL_GPIO_Init(GPIOG, &GPIO_InitStruct);

  /*Configure GPIO pins : D_IN1_Pin D_IN2_Pin D_IN3_Pin D_IN4_Pin
                           D_IN5_Pin D_IN6_Pin D_IN7_Pin D_IN8_Pin */
  GPIO_InitStruct.Pin = D_IN1_Pin|D_IN2_Pin|D_IN3_Pin|D_IN4_Pin
                          |D_IN5_Pin|D_IN6_Pin|D_IN7_Pin|D_IN8_Pin;
  GPIO_InitStruct.Mode = GPIO_MODE_INPUT;
  GPIO_InitStruct.Pull = GPIO_PULLDOWN;
  HAL_GPIO_Init(GPIOE, &GPIO_InitStruct);

  /*Configure GPIO pins : LCD_D0_Pin LCD_D1_Pin LCD_D2_Pin LCD_D3_Pin
                           LCD_D4_Pin LCD_D5_Pin LCD_D6_Pin LCD_D7_Pin
                           DA_LD_Pin DA_LOAD_Pin DA_DATA_Pin DA_CLK_Pin */
  GPIO_InitStruct.Pin = LCD_D0_Pin|LCD_D1_Pin|LCD_D2_Pin|LCD_D3_Pin
                          |LCD_D4_Pin|LCD_D5_Pin|LCD_D6_Pin|LCD_D7_Pin
                          |DA_LD_Pin|DA_LOAD_Pin|DA_DATA_Pin|DA_CLK_Pin;
  GPIO_InitStruct.Mode = GPIO_MODE_OUTPUT_PP;
  GPIO_InitStruct.Pull = GPIO_NOPULL;
  GPIO_InitStruct.Speed = GPIO_SPEED_FREQ_HIGH;
  HAL_GPIO_Init(GPIOD, &GPIO_InitStruct);

  /*Configure GPIO pin : D_OUT1_Pin */
  GPIO_InitStruct.Pin = D_OUT1_Pin;
  GPIO_InitStruct.Mode = GPIO_MODE_OUTPUT_PP;
  GPIO_InitStruct.Pull = GPIO_PULLUP;
  GPIO_InitStruct.Speed = GPIO_SPEED_FREQ_HIGH;
  HAL_GPIO_Init(D_OUT1_GPIO_Port, &GPIO_InitStruct);

  /*Configure GPIO pins : D_OUT2_Pin D_OUT3_Pin D_OUT4_Pin */
  GPIO_InitStruct.Pin = D_OUT2_Pin|D_OUT3_Pin|D_OUT4_Pin;
  GPIO_InitStruct.Mode = GPIO_MODE_OUTPUT_PP;
  GPIO_InitStruct.Pull = GPIO_PULLUP;
  GPIO_InitStruct.Speed = GPIO_SPEED_FREQ_HIGH;
  HAL_GPIO_Init(GPIOA, &GPIO_InitStruct);

  /*Configure GPIO pins : KEY2_Pin KEY3_Pin KEY4_Pin */
  GPIO_InitStruct.Pin = KEY2_Pin|KEY3_Pin|KEY4_Pin;
  GPIO_InitStruct.Mode = GPIO_MODE_INPUT;
  GPIO_InitStruct.Pull = GPIO_PULLDOWN;
  HAL_GPIO_Init(GPIOD, &GPIO_InitStruct);

  /*Configure GPIO pin : RMII_RESET_Pin */
  GPIO_InitStruct.Pin = RMII_RESET_Pin;
  GPIO_InitStruct.Mode = GPIO_MODE_OUTPUT_PP;
  GPIO_InitStruct.Pull = GPIO_PULLDOWN;
  GPIO_InitStruct.Speed = GPIO_SPEED_FREQ_HIGH;
  HAL_GPIO_Init(RMII_RESET_GPIO_Port, &GPIO_InitStruct);

}

void _Error_Handler(char *file, int line)
{
  /* USER CODE BEGIN Error_Handler_Debug */
  /* User can add his own implementation to report the HAL error return state */
  //printf("fileName:%s, fileLine:%d", file, line);
  while(1)
  {
  }
  /* USER CODE END Error_Handler_Debug */
}

#ifdef  USE_FULL_ASSERT
/**
  * @brief  Reports the name of the source file and the source line number
  *         where the assert_param error has occurred.
  * @param  file: pointer to the source file name
  * @param  line: assert_param error line source number
  * @retval None
  */
void assert_failed(uint8_t* file, uint32_t line)
{
  /* USER CODE BEGIN 6 */
  /* User can add his own implementation to report the file name and line number,*/
   // printf("Wrong parameters value: file %s on line %d\r\n", file, line)
  /* USER CODE END 6 */
}
#endif /* USE_FULL_ASSERT */

/************************ (C) COPYRIGHT STMicroelectronics *****END OF FILE****/
